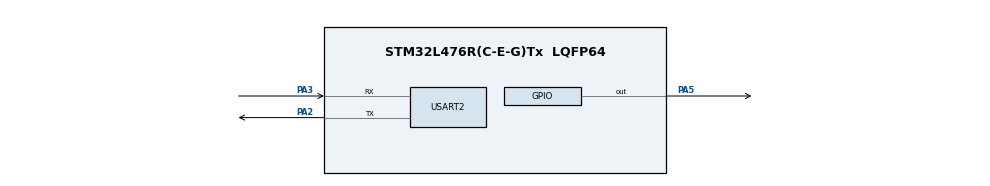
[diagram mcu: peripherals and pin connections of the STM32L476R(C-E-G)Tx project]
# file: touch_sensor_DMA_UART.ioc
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ADC1.Channel-1\#ChannelRegularConversion=ADC_CHANNEL_TEMPSENSOR
ADC1.ClockPrescaler=ADC_CLOCK_ASYNC_DIV2
ADC1.DMAContinuousRequests=ENABLE
ADC1.ExternalTrigConv=ADC_EXTERNALTRIG_T2_TRGO
ADC1.NbrOfConversionFlag=1
ADC1.OffsetNumber-1\#ChannelRegularConversion=ADC_OFFSET_NONE
ADC1.Rank-1\#ChannelRegularConversion=1
ADC1.SamplingTime-1\#ChannelRegularConversion=ADC_SAMPLETIME_24CYCLES_5
ADC1.master=1
Dma.ADC1.1.Direction=DMA_PERIPH_TO_MEMORY
Dma.ADC1.1.Instance=DMA1_Channel1
Dma.ADC1.1.MemDataAlignment=DMA_MDATAALIGN_HALFWORD
Dma.ADC1.1.MemInc=DMA_MINC_ENABLE
Dma.ADC1.1.Mode=DMA_NORMAL
Dma.ADC1.1.PeriphDataAlignment=DMA_PDATAALIGN_HALFWORD
Dma.ADC1.1.PeriphInc=DMA_PINC_DISABLE
Dma.ADC1.1.Priority=DMA_PRIORITY_LOW
Dma.Request0=USART2_TX
Dma.Request1=ADC1
Dma.USART2_TX.0.Direction=DMA_MEMORY_TO_PERIPH
Dma.USART2_TX.0.Instance=DMA1_Channel7
Dma.USART2_TX.0.MemDataAlignment=DMA_MDATAALIGN_BYTE
Dma.USART2_TX.0.MemInc=DMA_MINC_ENABLE
Dma.USART2_TX.0.Mode=DMA_NORMAL
Dma.USART2_TX.0.PeriphDataAlignment=DMA_PDATAALIGN_BYTE
Dma.USART2_TX.0.PeriphInc=DMA_PINC_DISABLE
Dma.USART2_TX.0.Priority=DMA_PRIORITY_LOW
Mcu.Family=STM32L4
Mcu.Name=STM32L476R(C-E-G)Tx
Mcu.Package=LQFP64
NVIC.DMA1_Channel1_IRQn=true\:0\:0\:false\:false\:true\:false\:true
NVIC.DMA1_Channel7_IRQn=true\:0\:0\:false\:false\:true\:false\:true
NVIC.PriorityGroup=NVIC_PRIORITYGROUP_4
NVIC.USART2_IRQn=true\:0\:0\:false\:false\:true\:true\:true
PA13\ (JTMS-SWDIO).Mode=Serial_Wire
PA13\ (JTMS-SWDIO).Signal=SYS_JTMS-SWDIO
PA14\ (JTCK-SWCLK).Mode=Serial_Wire
PA14\ (JTCK-SWCLK).Signal=SYS_JTCK-SWCLK
PA2.Mode=Asynchronous
PA2.Signal=USART2_TX
PA3.Mode=Asynchronous
PA3.Signal=USART2_RX
PA5.Signal=GPIO_Output
ProjectManager.HeapSize=0x200
ProjectManager.StackSize=0x400
ProjectManager.TargetToolchain=STM32CubeIDE
RCC.ADCFreq_Value=32000000
RCC.HSE_VALUE=8000000
RCC.HSI_VALUE=16000000
RCC.LSE_VALUE=32768
RCC.MSI_VALUE=4000000
RCC.PLLSAI1N=16
RCC.USBFreq_Value=32000000
RCC.VCOOutputFreq_Value=32000000
TIM2.Period=999
TIM2.Prescaler=3999
TIM2.TIM_MasterOutputTrigger=TIM_TRGO_UPDATE
TIM2.TIM_MasterSlaveMode=TIM_MASTERSLAVEMODE_ENABLE
USART2.VirtualMode-Asynchronous=VM_ASYNC
VP_ADC1_TempSens_Input.Mode=IN-TempSens
VP_TIM2_VS_ClockSourceINT.Mode=Internal
board=custom

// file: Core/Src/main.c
/* USER CODE BEGIN Header */
/**
  ******************************************************************************
  * @file           : main.c
  * @brief          : Main program body
  ******************************************************************************
  * @attention
  *
  * <h2><center>&copy; Copyright (c) 2021 STMicroelectronics.
  * All rights reserved.</center></h2>
  *
  * This software component is licensed by ST under BSD 3-Clause license,
  * the "License"; You may not use this file except in compliance with the
  * License. You may obtain a copy of the License at:
  *                        opensource.org/licenses/BSD-3-Clause
  *
  ******************************************************************************
  */
/* USER CODE END Header */

#include "main.h"

/* USER CODE BEGIN Includes */
#include <stdio.h>
#include <string.h>
#include <stdint.h>
#include <stdlib.h>
#include "arm_math.h"
/* USER CODE END Includes */

/* USER CODE BEGIN PTD */
#define ADC_BUF_LEN 26
#define ADC_BUF_LEN_HALF ADC_BUF_LEN/2
#define __VREFANALOG_VOLTAGE__ 3300
/* USER CODE END PTD */

ADC_HandleTypeDef hadc1;
DMA_HandleTypeDef hdma_adc1;

TIM_HandleTypeDef htim2;

UART_HandleTypeDef huart2;
DMA_HandleTypeDef hdma_usart2_tx;

/* USER CODE BEGIN PV */
uint16_t adc_buf[ADC_BUF_LEN];
int buff_sel = 0;
uint16_t z[ADC_BUF_LEN];
uint8_t Txdata[];
/* USER CODE END PV */

void SystemClock_Config(void);
static void MX_GPIO_Init(void);
static void MX_DMA_Init(void);
static void MX_ADC1_Init(void);
static void MX_TIM2_Init(void);
static void MX_USART2_UART_Init(void);
/* USER CODE BEGIN PFP */
void Data_Elab(void);
void Data_TR(void);
/* USER CODE END PFP */

int main(void)
{

  /* MCU Configuration--------------------------------------------------------*/

  /* Reset of all peripherals, Initializes the Flash interface and the Systick. */
  HAL_Init();

  /* Configure the system clock */
  SystemClock_Config();

  /* Initialize all configured peripherals */
  MX_GPIO_Init();
  MX_DMA_Init();
  MX_ADC1_Init();
  MX_TIM2_Init();
  MX_USART2_UART_Init();
  /* USER CODE BEGIN 2 */
  	  if (HAL_ADCEx_Calibration_Start(&hadc1, ADC_SINGLE_ENDED) != HAL_OK)
  		  HAL_GPIO_WritePin(GPIOA, GPIO_PIN_5, SET);
  	  if (HAL_ADC_Start_DMA(&hadc1, adc_buf, ADC_BUF_LEN) != HAL_OK)
  		  HAL_GPIO_TogglePin(GPIOA, GPIO_PIN_5);
  	  HAL_TIM_Base_Start(&htim2);
  /* USER CODE END 2 */

  /* Infinite loop */
  while (1)
  {

  }
}

void SystemClock_Config(void)
{
  RCC_OscInitTypeDef RCC_OscInitStruct = {0};
  RCC_ClkInitTypeDef RCC_ClkInitStruct = {0};
  RCC_PeriphCLKInitTypeDef PeriphClkInit = {0};

  /** Initializes the CPU, AHB and APB busses clocks
  */
  RCC_OscInitStruct.OscillatorType = RCC_OSCILLATORTYPE_MSI;
  RCC_OscInitStruct.MSIState = RCC_MSI_ON;
  RCC_OscInitStruct.MSICalibrationValue = 0;
  RCC_OscInitStruct.MSIClockRange = RCC_MSIRANGE_6;
  RCC_OscInitStruct.PLL.PLLState = RCC_PLL_NONE;
  if (HAL_RCC_OscConfig(&RCC_OscInitStruct) != HAL_OK)
  {
    Error_Handler();
  }
  /** Initializes the CPU, AHB and APB busses clocks
  */
  RCC_ClkInitStruct.ClockType = RCC_CLOCKTYPE_HCLK|RCC_CLOCKTYPE_SYSCLK
                              |RCC_CLOCKTYPE_PCLK1|RCC_CLOCKTYPE_PCLK2;
  RCC_ClkInitStruct.SYSCLKSource = RCC_SYSCLKSOURCE_MSI;
  RCC_ClkInitStruct.AHBCLKDivider = RCC_SYSCLK_DIV1;
  RCC_ClkInitStruct.APB1CLKDivider = RCC_HCLK_DIV1;
  RCC_ClkInitStruct.APB2CLKDivider = RCC_HCLK_DIV1;

  if (HAL_RCC_ClockConfig(&RCC_ClkInitStruct, FLASH_LATENCY_0) != HAL_OK)
  {
    Error_Handler();
  }
  PeriphClkInit.PeriphClockSelection = RCC_PERIPHCLK_USART2|RCC_PERIPHCLK_ADC;
  PeriphClkInit.Usart2ClockSelection = RCC_USART2CLKSOURCE_PCLK1;
  PeriphClkInit.AdcClockSelection = RCC_ADCCLKSOURCE_PLLSAI1;
  PeriphClkInit.PLLSAI1.PLLSAI1Source = RCC_PLLSOURCE_MSI;
  PeriphClkInit.PLLSAI1.PLLSAI1M = 1;
  PeriphClkInit.PLLSAI1.PLLSAI1N = 16;
  PeriphClkInit.PLLSAI1.PLLSAI1P = RCC_PLLP_DIV7;
  PeriphClkInit.PLLSAI1.PLLSAI1Q = RCC_PLLQ_DIV2;
  PeriphClkInit.PLLSAI1.PLLSAI1R = RCC_PLLR_DIV2;
  PeriphClkInit.PLLSAI1.PLLSAI1ClockOut = RCC_PLLSAI1_ADC1CLK;
  if (HAL_RCCEx_PeriphCLKConfig(&PeriphClkInit) != HAL_OK)
  {
    Error_Handler();
  }
  /** Configure the main internal regulator output voltage
  */
  if (HAL_PWREx_ControlVoltageScaling(PWR_REGULATOR_VOLTAGE_SCALE1) != HAL_OK)
  {
    Error_Handler();
  }
}

static void MX_ADC1_Init(void)
{

  ADC_MultiModeTypeDef multimode = {0};
  ADC_ChannelConfTypeDef sConfig = {0};

  /** Common config
  */
  hadc1.Instance = ADC1;
  hadc1.Init.ClockPrescaler = ADC_CLOCK_ASYNC_DIV2;
  hadc1.Init.Resolution = ADC_RESOLUTION_12B;
  hadc1.Init.DataAlign = ADC_DATAALIGN_RIGHT;
  hadc1.Init.ScanConvMode = ADC_SCAN_DISABLE;
  hadc1.Init.EOCSelection = ADC_EOC_SINGLE_CONV;
  hadc1.Init.LowPowerAutoWait = DISABLE;
  hadc1.Init.ContinuousConvMode = DISABLE;
  hadc1.Init.NbrOfConversion = 1;
  hadc1.Init.DiscontinuousConvMode = DISABLE;
  hadc1.Init.NbrOfDiscConversion = 1;
  hadc1.Init.ExternalTrigConv = ADC_EXTERNALTRIG_T2_TRGO;
  hadc1.Init.ExternalTrigConvEdge = ADC_EXTERNALTRIGCONVEDGE_RISING;
  hadc1.Init.DMAContinuousRequests = ENABLE;
  hadc1.Init.Overrun = ADC_OVR_DATA_PRESERVED;
  hadc1.Init.OversamplingMode = DISABLE;
  if (HAL_ADC_Init(&hadc1) != HAL_OK)
  {
    Error_Handler();
  }
  /** Configure the ADC multi-mode
  */
  multimode.Mode = ADC_MODE_INDEPENDENT;
  if (HAL_ADCEx_MultiModeConfigChannel(&hadc1, &multimode) != HAL_OK)
  {
    Error_Handler();
  }
  /** Configure Regular Channel
  */
  sConfig.Channel = ADC_CHANNEL_TEMPSENSOR;
  sConfig.Rank = ADC_REGULAR_RANK_1;
  sConfig.SamplingTime = ADC_SAMPLETIME_24CYCLES_5;
  sConfig.SingleDiff = ADC_SINGLE_ENDED;
  sConfig.OffsetNumber = ADC_OFFSET_NONE;
  sConfig.Offset = 0;
  if (HAL_ADC_ConfigChannel(&hadc1, &sConfig) != HAL_OK)
  {
    Error_Handler();
  }

}

static void MX_TIM2_Init(void)
{

  TIM_ClockConfigTypeDef sClockSourceConfig = {0};
  TIM_MasterConfigTypeDef sMasterConfig = {0};

  htim2.Instance = TIM2;
  htim2.Init.Prescaler = 3999;
  htim2.Init.CounterMode = TIM_COUNTERMODE_UP;
  htim2.Init.Period = 999;
  htim2.Init.ClockDivision = TIM_CLOCKDIVISION_DIV1;
  htim2.Init.AutoReloadPreload = TIM_AUTORELOAD_PRELOAD_DISABLE;
  if (HAL_TIM_Base_Init(&htim2) != HAL_OK)
  {
    Error_Handler();
  }
  sClockSourceConfig.ClockSource = TIM_CLOCKSOURCE_INTERNAL;
  if (HAL_TIM_ConfigClockSource(&htim2, &sClockSourceConfig) != HAL_OK)
  {
    Error_Handler();
  }
  sMasterConfig.MasterOutputTrigger = TIM_TRGO_UPDATE;
  sMasterConfig.MasterSlaveMode = TIM_MASTERSLAVEMODE_ENABLE;
  if (HAL_TIMEx_MasterConfigSynchronization(&htim2, &sMasterConfig) != HAL_OK)
  {
    Error_Handler();
  }

}

static void MX_USART2_UART_Init(void)
{

  huart2.Instance = USART2;
  huart2.Init.BaudRate = 115200;
  huart2.Init.WordLength = UART_WORDLENGTH_8B;
  huart2.Init.StopBits = UART_STOPBITS_1;
  huart2.Init.Parity = UART_PARITY_NONE;
  huart2.Init.Mode = UART_MODE_TX_RX;
  huart2.Init.HwFlowCtl = UART_HWCONTROL_NONE;
  huart2.Init.OverSampling = UART_OVERSAMPLING_16;
  huart2.Init.OneBitSampling = UART_ONE_BIT_SAMPLE_DISABLE;
  huart2.AdvancedInit.AdvFeatureInit = UART_ADVFEATURE_NO_INIT;
  if (HAL_UART_Init(&huart2) != HAL_OK)
  {
    Error_Handler();
  }

}

static void MX_DMA_Init(void)
{

  /* DMA controller clock enable */
  __HAL_RCC_DMA1_CLK_ENABLE();

  /* DMA interrupt init */
  /* DMA1_Channel1_IRQn interrupt configuration */
  HAL_NVIC_SetPriority(DMA1_Channel1_IRQn, 0, 0);
  HAL_NVIC_EnableIRQ(DMA1_Channel1_IRQn);
  /* DMA1_Channel7_IRQn interrupt configuration */
  HAL_NVIC_SetPriority(DMA1_Channel7_IRQn, 0, 0);
  HAL_NVIC_EnableIRQ(DMA1_Channel7_IRQn);

}

static void MX_GPIO_Init(void)
{
  GPIO_InitTypeDef GPIO_InitStruct = {0};

  /* GPIO Ports Clock Enable */
  __HAL_RCC_GPIOA_CLK_ENABLE();

  /*Configure GPIO pin Output Level */
  HAL_GPIO_WritePin(GPIOA, GPIO_PIN_5, GPIO_PIN_RESET);

  /*Configure GPIO pin : PA5 */
  GPIO_InitStruct.Pin = GPIO_PIN_5;
  GPIO_InitStruct.Mode = GPIO_MODE_OUTPUT_PP;
  GPIO_InitStruct.Pull = GPIO_NOPULL;
  GPIO_InitStruct.Speed = GPIO_SPEED_FREQ_LOW;
  HAL_GPIO_Init(GPIOA, &GPIO_InitStruct);

}

/* USER CODE BEGIN 4 */
// When half of the buffer is filled
void HAL_ADC_ConvHalfCpltCallback(ADC_HandleTypeDef* hadc)
{
	//HAL_GPIO_WritePin(GPIOA, GPIO_PIN_5, GPIO_PIN_SET); // Toggle the led on board
	buff_sel =0;
	Data_Elab();

}

void HAL_ADC_ConvCpltCallback(ADC_HandleTypeDef* hadc)
{
	///HAL_GPIO_WritePin(GPIOA, GPIO_PIN_5, GPIO_PIN_RESET); // Toggle the led on board
	buff_sel = 1;
	Data_Elab();

}

void Data_Elab(void){
	int i=0;
	if (buff_sel == 0){
		for (i=0; i< ADC_BUF_LEN_HALF; i++){
			z[i] =  __LL_ADC_CALC_TEMPERATURE(__VREFANALOG_VOLTAGE__, (adc_buf[i]), LL_ADC_RESOLUTION_12B);
			sprintf(Txdata, " %5x\r\n", z[i]);
			HAL_UART_Transmit(&huart2,  Txdata, strlen(Txdata),100);
		}

	}
	else {
		for (i= ADC_BUF_LEN_HALF; ADC_BUF_LEN; i++){
			z[i] =  __LL_ADC_CALC_TEMPERATURE(__VREFANALOG_VOLTAGE__, (adc_buf[i]), LL_ADC_RESOLUTION_12B) ;
			sprintf(Txdata, "%5x\r\n", z[i]);
			HAL_UART_Transmit(&huart2,  Txdata, strlen(Txdata),100);
		}

	}
}

/* USER CODE END 4 */

void Error_Handler(void)
{
}

/************************ (C) COPYRIGHT STMicroelectronics *****END OF FILE****/
